# TC37X register map
File version: 1.0.0
CPU: CM4 r0p1, little endian, MPU, FPU, VTOR, 3 interrupt priority bits
Registers are 16-bit, read-write, reset 0x0 unless marked. A register's access mark holds for its fields unless they carry their own. Offsets are from the block's base; [hi:lo] are bit positions; {n}, {i} and the like mark numbered series.

## MSC0 — ce_msc64
Base 0xF0002600
Same registers: MSC1 0xF0002700
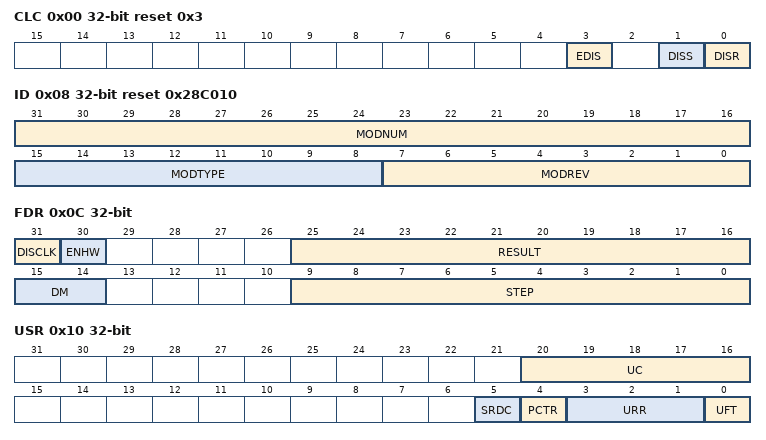
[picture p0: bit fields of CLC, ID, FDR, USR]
0x00 CLC 32-bit reset 0x3 — Clock Control Register
  [3] EDIS — Sleep Mode Enable Control - EDIS
  [1] DISS ro — Module Disable Status Bit - DISS
  [0] DISR — Module Disable Request Bit - DISR
0x08 ID 32-bit ro reset 0x28C010 (reset mask 0xFFFFFFF0) — Module Identification Register
  [31:16] MODNUM — Module Number Value - MODNUM
  [15:8] MODTYPE — Module Type - MODTYPE
  [7:0] MODREV — Module Revision Number - MODREV
0x0C FDR 32-bit — Fractional Divider Register
  [31] DISCLK — Disable Clock - DISCLK
  [30] ENHW — Enable Hardware Clock Control - ENHW
  [25:16] RESULT ro — Result Value - RESULT
  [15:14] DM — Divider Mode - DM
  [9:0] STEP — Step Value - STEP
0x10 USR 32-bit — Upstream Status Register
  [20:16] UC ro — Upstream Counter - UC
  [5] SRDC — Service Request Delay Control - SRDC
  [4] PCTR — Parity Control - PCTR
  [3:1] URR — Upstream Channel Receiving Rate - URR
  [0] UFT — Upstream Channel Frame Type - UFT
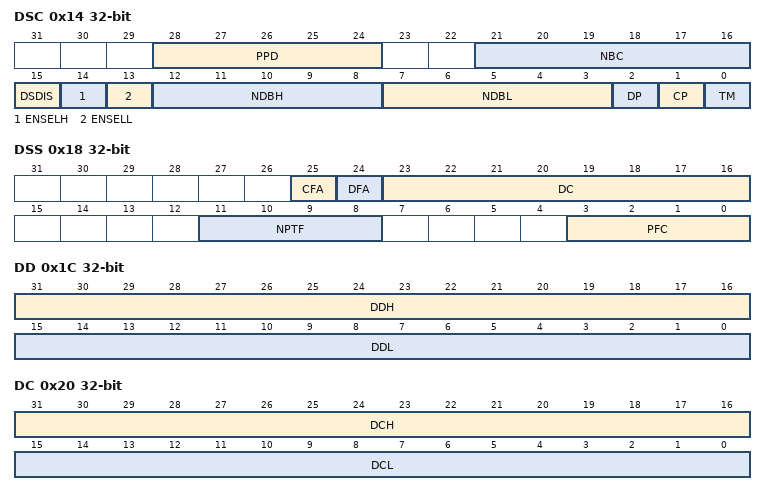
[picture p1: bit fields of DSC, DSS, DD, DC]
0x14 DSC 32-bit — Downstream Control Register
  [28:24] PPD — Passive Phase Length at Data Frames - PPD
  [21:16] NBC — Number of Bits Shifted at Command Frames - NBC
  [15] DSDIS ro — Downstream Disable - DSDIS
  [14] ENSELH — Enable SRH Active Phase Selection Bit - ENSELH
  [13] ENSELL — Enable SRL Active Phase Selection Bit - ENSELL
  [12:8] NDBH — Number of SRH Bits Shifted at Data Frames - NDBH
  [7:3] NDBL — Number of SRL Bits Shifted at Data Frames - NDBL
  [2] DP ro — Data Pending - DP
  [1] CP ro — Command Pending - CP
  [0] TM — Transmission Mode - TM
0x18 DSS 32-bit — Downstream Status Register
  [25] CFA ro — Command Frame Active - CFA
  [24] DFA ro — Data Frame Active - DFA
  [23:16] DC ro — Downstream Counter - DC
  [11:8] NPTF — Number Of Passive Time Frames - NPTF
  [3:0] PFC ro — Passive Time Frame Counter - PFC
0x1C DD 32-bit — Downstream Data Register
  [31:16] DDH — Downstream Data for SRH Shift Register - DDH
  [15:0] DDL — Downstream Data for SRL Shift Register - DDL
0x20 DC 32-bit — Downstream Command Register
  [31:16] DCH — Downstream Command for SRH Shift Register - DCH
  [15:0] DCL — Downstream Command for SRL Shift Register - DCL
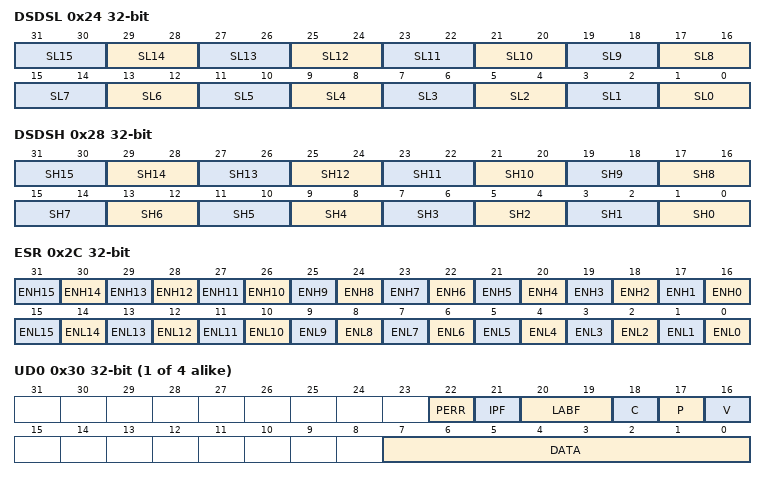
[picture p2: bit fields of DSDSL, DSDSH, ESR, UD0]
0x24 DSDSL 32-bit — Downstream Select Data Source Low Register
  [2n+1:2n] SL{n} (n=0..15) — Select Source for SRL - SL{n}
0x28 DSDSH 32-bit — Downstream Select Data Source High Register
  [2n+1:2n] SH{n} (n=0..15) — Select Source for SRH - SH{n}
0x2C ESR 32-bit — Emergency Stop Register
  [n+16] ENH{n} (n=0..15) — Emergency Stop Enable for Bit {n} in SRH - ENH{n}
  [n] ENL{n} (n=0..15) — Emergency Stop Enable for Bit {n} in SRL - ENL{n}
{0x30+4i} UD{i} 32-bit (i=0..3) — Upstream Data Register {i}
  [22] PERR ro — Parity Error - PERR
  [21] IPF ro — Internal Parity Flag - IPF
  [20:19] LABF ro — Lower Address Bit Field - LABF
  [18] C wo — Clear Bit - C
  [17] P ro — Parity Bit - P
  [16] V ro — Valid Bit - V
  [7:0] DATA ro — Received Data - DATA
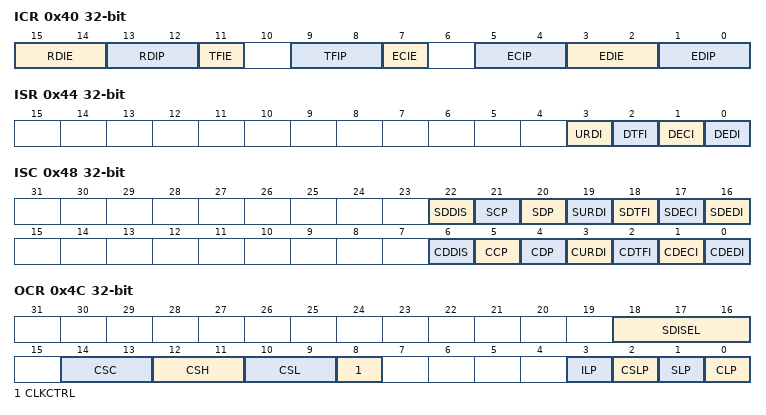
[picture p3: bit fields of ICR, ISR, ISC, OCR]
0x40 ICR 32-bit — Interrupt Control Register
  [15:14] RDIE — Receive Data Interrupt Enable - RDIE
  [13:12] RDIP — Receive Data Interrupt Pointer - RDIP
  [11] TFIE — Time Frame Interrupt Enable - TFIE
  [9:8] TFIP — Time Frame Interrupt Pointer - TFIP
  [7] ECIE — Command Frame Interrupt Enable - ECIE
  [5:4] ECIP — Command Frame Interrupt Node Pointer - ECIP
  [3:2] EDIE — Data Frame Interrupt Enable - EDIE
  [1:0] EDIP — Data Frame Interrupt Node Pointer - EDIP
0x44 ISR 32-bit ro — Interrupt Status Register
  [3] URDI — Receive Data Interrupt Flag - URDI
  [2] DTFI — Time Frame Interrupt Flag - DTFI
  [1] DECI — Command Frame Interrupt Flag - DECI
  [0] DEDI — Data Frame Interrupt Flag - DEDI
0x48 ISC 32-bit wo — Interrupt Set Clear Register
  [22] SDDIS — Set DSDIS Flag - SDDIS
  [21] SCP — Set CP Flag - SCP
  [20] SDP — Set DP Bit - SDP
  [19] SURDI — Set URDI Flag - SURDI
  [18] SDTFI — Set DTFI Flag - SDTFI
  [17] SDECI — Set DECI Flag - SDECI
  [16] SDEDI — Set DEDI Flag - SDEDI
  [6] CDDIS — Clear DSDIS Flag - CDDIS
  [5] CCP — Clear CP Flag - CCP
  [4] CDP — Clear DP Flag - CDP
  [3] CURDI — Clear URDI Flag - CURDI
  [2] CDTFI — Clear DTFI Flag - CDTFI
  [1] CDECI — Clear DECI Flag - CDECI
  [0] CDEDI — Clear DEDI Flag - CDEDI
0x4C OCR 32-bit — Output Control Register
  [18:16] SDISEL — Serial Data Input Selection - SDISEL
  [14:13] CSC — Chip Enable Selection for ENC - CSC
  [12:11] CSH — Chip Enable Selection for ENH - CSH
  [10:9] CSL — Chip Enable Selection for ENL - CSL
  [8] CLKCTRL — Clock Control - CLKCTRL
  [3] ILP — SDI Line Polarity - ILP
  [2] CSLP — Chip Selection Lines Polarity - CSLP
  [1] SLP — SOP Line Polarity - SLP
  [0] CLP — FCLP Line Polarity - CLP
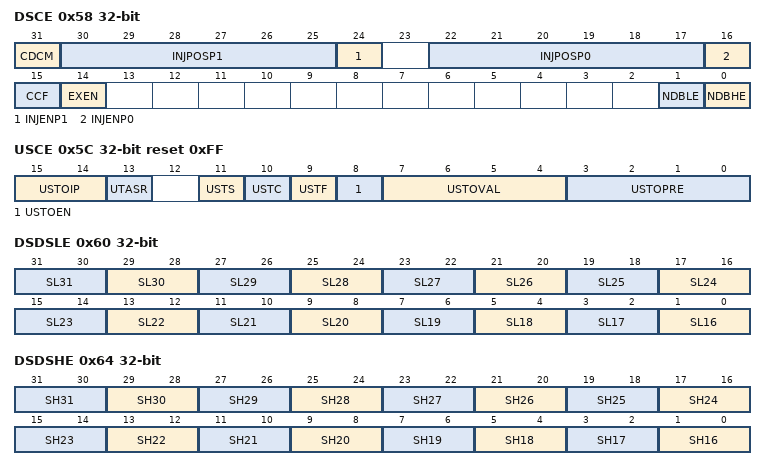
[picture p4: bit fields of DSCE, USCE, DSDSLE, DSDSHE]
0x58 DSCE 32-bit — Downstream Control Enhanced Register 1
  [31] CDCM — Command-Data-Command in Data Repetition Mode - CDCM
  [30:25] INJPOSP1 — Injection Position of the Pin 1 Signal - INJPOSP1
  [24] INJENP1 — Injection Enable of the Pin 1 Signal - INJENP1
  [22:17] INJPOSP0 — Injection Position of the Pin 0 Signal - INJPOSP0
  [16] INJENP0 — Injection Enable of the Pin 0 Signal - INJENP0
  [15] CCF ro — Command-Command Flag - CCF
  [14] EXEN — Extension Enable - EXEN
  [1] NDBLE — Number of SRL Bits Shifted at Data Frames Extension - NDBLE
  [0] NDBHE — Number of SRH Bits Shifted at Data Frames Extension - NDBHE
0x5C USCE 32-bit reset 0xFF — Upstream Control Enhanced Register 1
  [15:14] USTOIP — Upstream Time-out Interrupt Node Pointer - USTOIP
  [13] UTASR — Upstream Time-out Alternate Service Request - UTASR
  [11] USTS wo — Upstream Time-out Set - USTS
  [10] USTC wo — Upstream Time-out Clear - USTC
  [9] USTF ro — Upstream Time-out Flag - USTF
  [8] USTOEN — Upstream Time-out Interrupt Enable - USTOEN
  [7:4] USTOVAL — Upstream Time-out Value - USTOVAL
  [3:0] USTOPRE — Upstream Time-out Prescaler - USTOPRE
0x60 DSDSLE 32-bit — Downstream Select Data Source Low Extension Register
  [2n-31:2n-32] SL{n} (n=16..31) — Select Source for SRL - SL{n}
0x64 DSDSHE 32-bit — Downstream Select Data Source High Extension Register
  [2n-31:2n-32] SH{n} (n=16..31) — Select Source for SRH - SH{n}
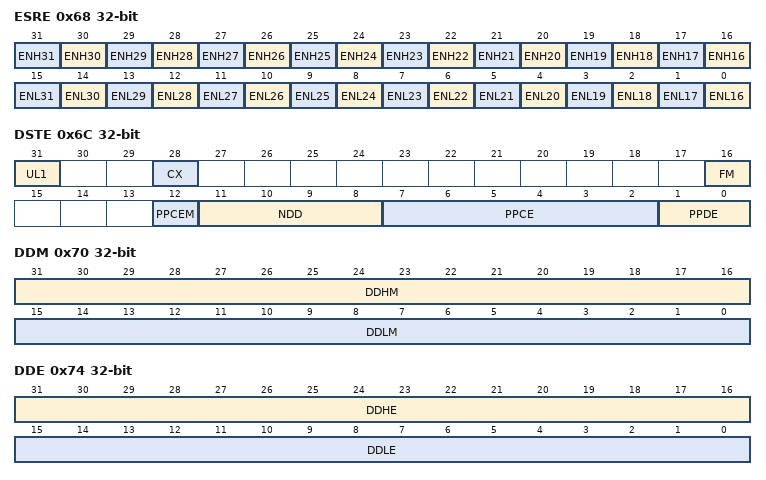
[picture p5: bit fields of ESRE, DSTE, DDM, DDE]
0x68 ESRE 32-bit — Emergency Stop Extension Register
  [n] ENH{n} (n=16..31) — Emergency Stop Enable for Bit {n} in SRH - ENH{n}
  [n-16] ENL{n} (n=16..31) — Emergency Stop Enable for Bit {n} in SRL - ENL{n}
0x6C DSTE 32-bit — Downstream Timing Extension Register
  [31] UL1 wo — Unlock CX and FM for one write access - UL1
  [28] CX — Command Extension Mode - CX
  [16] FM — Fast Mode - FM
  [12] PPCEM — PPCE Extension Bit on the MSB Side - PPCEM
  [11:8] NDD — N Divider Downstream - NDD
  [7:2] PPCE — Passive Phase Length at Control Frames Extension - PPCE
  [1:0] PPDE — Passive Phase Length at Data Frames Extension - PPDE
0x70 DDM 32-bit wo — Downstream Data Mirror Register
  [31:16] DDHM — Downstream Data Mirror for SRH Shift Register - DDHM
  [15:0] DDLM — Downstream Data Mirror for SRL Shift Register - DDLM
0x74 DDE 32-bit — Downstream Data Extension Register
  [31:16] DDHE — Downstream Data Extension for SRH Shift Register - DDHE
  [15:0] DDLE — Downstream Data Extension for SRL Shift Register - DDLE
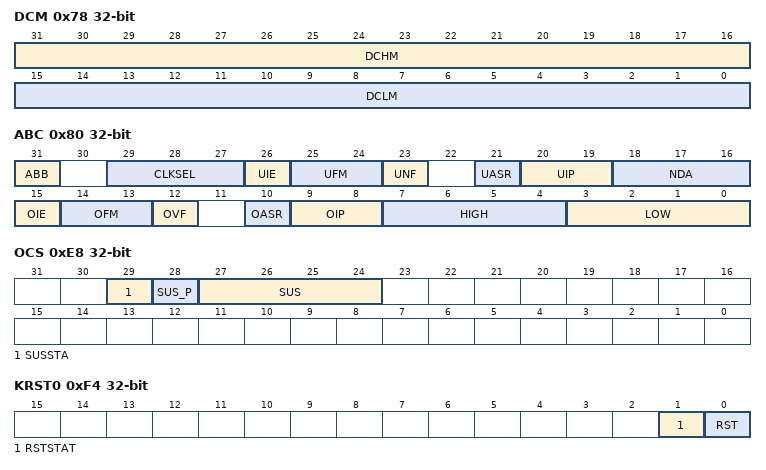
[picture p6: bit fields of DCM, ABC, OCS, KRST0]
0x78 DCM 32-bit wo — Downstream Command Mirror Register
  [31:16] DCHM — Downstream Command Mirror of the DC.DCH Bit Field - DCHM
  [15:0] DCLM — Downstream Command Mirror of the DC.DCL Bit Field - DCLM
0x7C DCE 32-bit — Downstream Command Extension Register
  [31:0] DCEH — Downstream Command Extension for SRH Shift Register - DCEH
0x80 ABC 32-bit — Asynchronous Block Configuration Register
  [31] ABB — Asynchronous Block Bypass - ABB
  [29:27] CLKSEL — Clock Select - CLKSEL
  [26] UIE — Underflow Interrupt Enable - UIE
  [25:24] UFM wo — Underflow Flag Modify - UFM
  [23] UNF ro — Underflow Flag - UNF
  [21] UASR — Underflow Alternate Service Request - UASR
  [20:19] UIP — Underflow Interrupt Node Pointer - UIP
  [18:16] NDA — N Divider ABRA - NDA
  [15] OIE — Overflow Interrupt Enable - OIE
  [14:13] OFM wo — Overflow Flag Modify - OFM
  [12] OVF ro — Overflow Flag - OVF
  [10] OASR — Overflow Alternate Service Request - OASR
  [9:8] OIP — Overflow Interrupt Node Pointer - OIP
  [7:4] HIGH — Duration of the High Phase of the Shift Clock - HIGH
  [3:0] LOW — Duration of the Low Phase of the Shift Clock - LOW
0xE8 OCS 32-bit — OCDS Control and Status
  [29] SUSSTA ro — Suspend State - SUSSTA
  [28] SUS_P wo — SUS Write Protection - SUS_P
  [27:24] SUS — OCDS Suspend Control - SUS
0xEC KRSTCLR 32-bit wo — Kernel Reset Status Clear Register
  [0] CLR — Kernel Reset Status Clear - CLR
0xF0 KRST1 32-bit — Kernel Reset Register 1
  [0] RST — Kernel Reset - RST
0xF4 KRST0 32-bit — Kernel Reset Register 0
  [1] RSTSTAT ro — Kernel Reset Status - RSTSTAT
  [0] RST — Kernel Reset - RST
0xF8 ACCEN1 32-bit ro — Access Enable Register 1
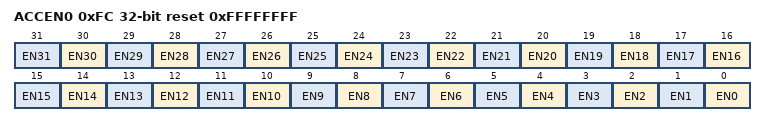
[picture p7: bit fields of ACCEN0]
0xFC ACCEN0 32-bit reset 0xFFFFFFFF — Access Enable Register 0
  [n] EN{n} (n=0..31) — Access Enable for Master TAG ID {n} - EN{n}
